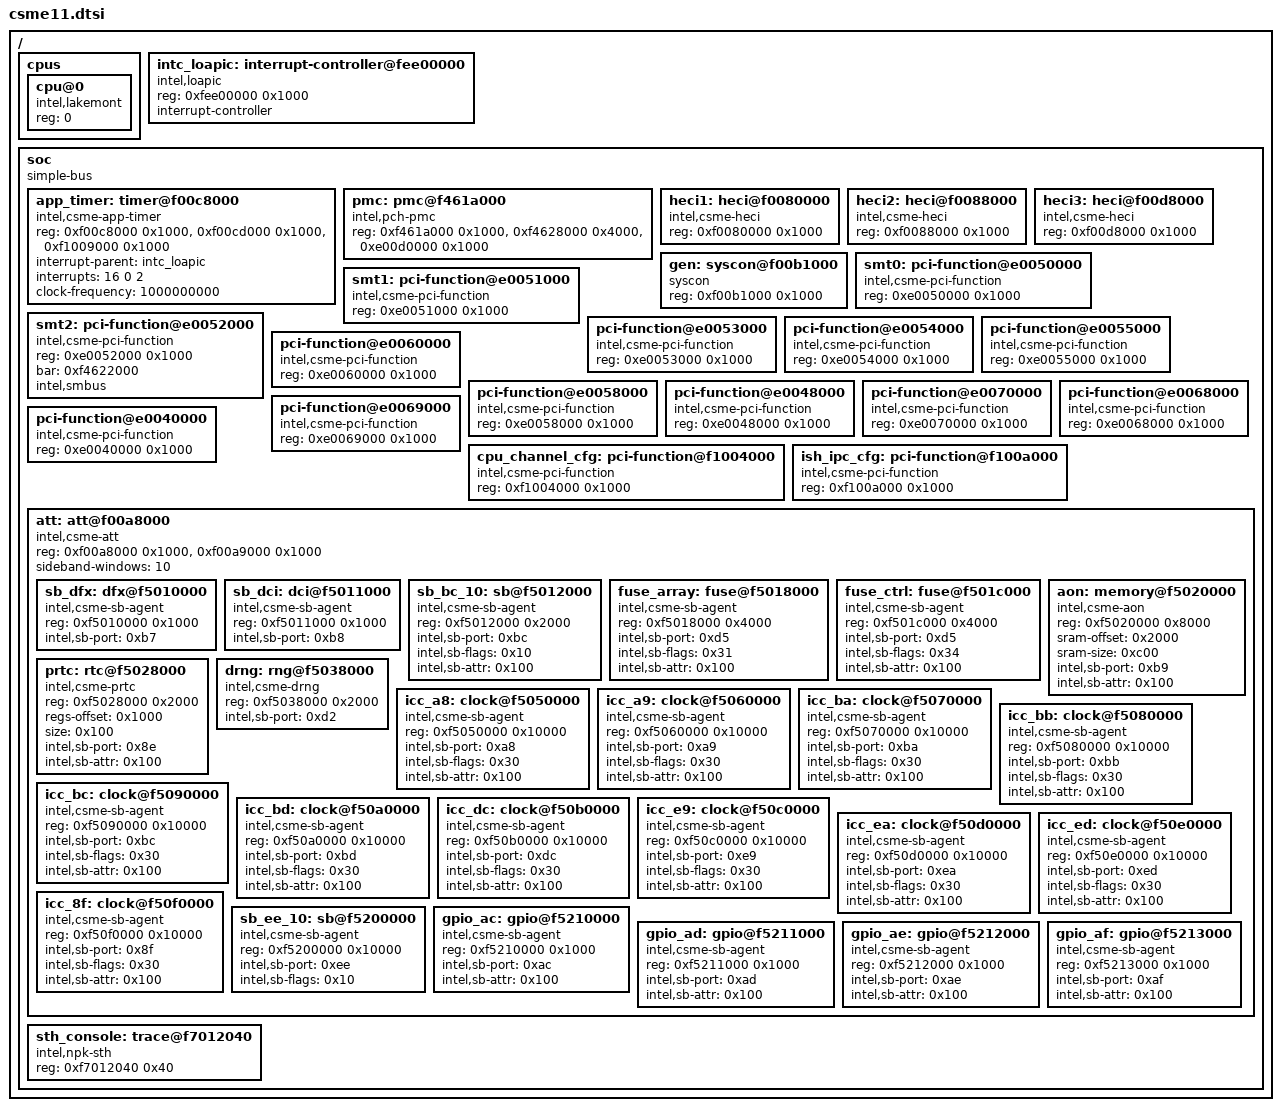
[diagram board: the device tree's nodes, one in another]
/*
 * Copyright The Zephyr Project Contributors
 *
 * SPDX-License-Identifier: Apache-2.0
 *
 * Intel CSME 11 (Sunrise Point PCH): the engine's view of its own address
 * space (csme-hardware-registers.md in the CSME reversing notes). Devices
 * behind ATT windows (the trace hub) are at the addresses the boot ROM maps
 * them to.
 */

#include <skeleton.dtsi>
#include <mem.h>

/ {
	cpus {
		#address-cells = <1>;
		#size-cells = <0>;

		cpu@0 {
			compatible = "intel,lakemont", "intel,x86";
			reg = <0>;
			device_type = "cpu";
		};
	};

	intc_loapic: interrupt-controller@fee00000 {
		compatible = "intel,loapic";
		reg = <0xfee00000 0x1000>;
		interrupt-controller;
		#interrupt-cells = <3>;
	};

	soc {
		compatible = "simple-bus";
		ranges;
		#address-cells = <1>;
		#size-cells = <1>;

		/* Private bus 0:01.1: BAR0, BAR5, configuration space. The
		 * interrupt is an MSI; IRQ numbers above the local APIC's LVT
		 * lines (0-5) are message-signalled only.
		 */
		app_timer: timer@f00c8000 {
			compatible = "intel,csme-app-timer";
			reg = <0xf00c8000 0x1000>, <0xf00cd000 0x1000>, <0xf1009000 0x1000>;
			reg-names = "regs", "ctl", "cfg";
			interrupt-parent = <&intc_loapic>;
			interrupts = <16 0 2>;
			/* the counter rate is inferred, not confirmed */
			clock-frequency = <1000000000>;
		};

		/* PCH PMC: root space 0:1a.0 (BAR0 registers, BAR1 SRAM) */
		pmc: pmc@f461a000 {
			compatible = "intel,pch-pmc";
			reg = <0xf461a000 0x1000>, <0xf4628000 0x4000>, <0xe00d0000 0x1000>;
			reg-names = "regs", "sram", "cfg";
		};

		/* HECI functions, engine side (fixed BARs on the private bus) */
		heci1: heci@f0080000 {
			compatible = "intel,csme-heci";
			reg = <0xf0080000 0x1000>;
		};

		heci2: heci@f0088000 {
			compatible = "intel,csme-heci";
			reg = <0xf0088000 0x1000>;
		};

		heci3: heci@f00d8000 {
			compatible = "intel,csme-heci";
			reg = <0xf00d8000 0x1000>;
		};

		/* CSME control (GEN): power-gate control, fabric drain */
		gen: syscon@f00b1000 {
			compatible = "syscon";
			reg = <0xf00b1000 0x1000>;
		};

		/* PCI functions the CSME kernel quiesces before a power transition
		 * (its device order), configuration space in the root ECAM or,
		 * for the last two, on the private bus
		 */
		smt0: pci-function@e0050000 {
			compatible = "intel,csme-pci-function";
			reg = <0xe0050000 0x1000>;
		};

		smt1: pci-function@e0051000 {
			compatible = "intel,csme-pci-function";
			reg = <0xe0051000 0x1000>;
		};

		smt2: pci-function@e0052000 {
			compatible = "intel,csme-pci-function";
			reg = <0xe0052000 0x1000>;
			bar = <0xf4622000>;
			intel,smbus;
		};

		pci-function@e0053000 {
			compatible = "intel,csme-pci-function";
			reg = <0xe0053000 0x1000>;
		};

		pci-function@e0054000 {
			compatible = "intel,csme-pci-function";
			reg = <0xe0054000 0x1000>;
		};

		pci-function@e0055000 {
			compatible = "intel,csme-pci-function";
			reg = <0xe0055000 0x1000>;
		};

		pci-function@e0060000 {
			compatible = "intel,csme-pci-function";
			reg = <0xe0060000 0x1000>;
		};

		pci-function@e0058000 {
			compatible = "intel,csme-pci-function";
			reg = <0xe0058000 0x1000>;
		};

		pci-function@e0048000 {
			compatible = "intel,csme-pci-function";
			reg = <0xe0048000 0x1000>;
		};

		pci-function@e0070000 {
			compatible = "intel,csme-pci-function";
			reg = <0xe0070000 0x1000>;
		};

		pci-function@e0068000 {
			compatible = "intel,csme-pci-function";
			reg = <0xe0068000 0x1000>;
		};

		pci-function@e0069000 {
			compatible = "intel,csme-pci-function";
			reg = <0xe0069000 0x1000>;
		};

		pci-function@e0040000 {
			compatible = "intel,csme-pci-function";
			reg = <0xe0040000 0x1000>;
		};

		cpu_channel_cfg: pci-function@f1004000 {
			compatible = "intel,csme-pci-function";
			reg = <0xf1004000 0x1000>;
		};

		ish_ipc_cfg: pci-function@f100a000 {
			compatible = "intel,csme-pci-function";
			reg = <0xf100a000 0x1000>;
		};

		/* Address translation table: primary and sideband windows. The
		 * sideband agents below are mapped on demand at these addresses
		 * (the ones the CSME kernel uses).
		 */
		att: att@f00a8000 {
			compatible = "intel,csme-att";
			reg = <0xf00a8000 0x1000>, <0xf00a9000 0x1000>;
			reg-names = "primary", "sideband";
			sideband-windows = <10>;
			#address-cells = <1>;
			#size-cells = <1>;
			ranges;

			/* DFX aggregator */
			sb_dfx: dfx@f5010000 {
				compatible = "intel,csme-sb-agent";
				reg = <0xf5010000 0x1000>;
				intel,sb-port = <0xb7>;
			};

			/* DCI */
			sb_dci: dci@f5011000 {
				compatible = "intel,csme-sb-agent";
				reg = <0xf5011000 0x1000>;
				intel,sb-port = <0xb8>;
			};

			/* Port 0xbc, flags 0x10 */
			sb_bc_10: sb@f5012000 {
				compatible = "intel,csme-sb-agent";
				reg = <0xf5012000 0x2000>;
				intel,sb-port = <0xbc>;
				intel,sb-flags = <0x10>;
				intel,sb-attr = <0x100>;
			};

			/* Fuse controller: shadow and sensed fuse data */
			fuse_array: fuse@f5018000 {
				compatible = "intel,csme-sb-agent";
				reg = <0xf5018000 0x4000>;
				intel,sb-port = <0xd5>;
				intel,sb-flags = <0x31>;
				intel,sb-attr = <0x100>;
			};

			/* Fuse controller: control (access grant, margin reads) */
			fuse_ctrl: fuse@f501c000 {
				compatible = "intel,csme-sb-agent";
				reg = <0xf501c000 0x4000>;
				intel,sb-port = <0xd5>;
				intel,sb-flags = <0x34>;
				intel,sb-attr = <0x100>;
			};

			/* AON agent: registers and always-on SRAM (+0x2000) */
			aon: memory@f5020000 {
				compatible = "intel,csme-aon";
				reg = <0xf5020000 0x8000>;
				sram-offset = <0x2000>;
				sram-size = <0xc00>;
				intel,sb-port = <0xb9>;
				intel,sb-attr = <0x100>;
			};

			/* PRTC: always-on registers (+0x1000) */
			prtc: rtc@f5028000 {
				compatible = "intel,csme-prtc";
				reg = <0xf5028000 0x2000>;
				regs-offset = <0x1000>;
				size = <0x100>;
				intel,sb-port = <0x8e>;
				intel,sb-attr = <0x100>;
			};

			/* DRNG */
			drng: rng@f5038000 {
				compatible = "intel,csme-drng";
				reg = <0xf5038000 0x2000>;
				intel,sb-port = <0xd2>;
			};

			/* ICC port 0xa8 */
			icc_a8: clock@f5050000 {
				compatible = "intel,csme-sb-agent";
				reg = <0xf5050000 0x10000>;
				intel,sb-port = <0xa8>;
				intel,sb-flags = <0x30>;
				intel,sb-attr = <0x100>;
			};

			/* ICC port 0xa9 */
			icc_a9: clock@f5060000 {
				compatible = "intel,csme-sb-agent";
				reg = <0xf5060000 0x10000>;
				intel,sb-port = <0xa9>;
				intel,sb-flags = <0x30>;
				intel,sb-attr = <0x100>;
			};

			/* ICC port 0xba */
			icc_ba: clock@f5070000 {
				compatible = "intel,csme-sb-agent";
				reg = <0xf5070000 0x10000>;
				intel,sb-port = <0xba>;
				intel,sb-flags = <0x30>;
				intel,sb-attr = <0x100>;
			};

			/* ICC port 0xbb */
			icc_bb: clock@f5080000 {
				compatible = "intel,csme-sb-agent";
				reg = <0xf5080000 0x10000>;
				intel,sb-port = <0xbb>;
				intel,sb-flags = <0x30>;
				intel,sb-attr = <0x100>;
			};

			/* ICC port 0xbc */
			icc_bc: clock@f5090000 {
				compatible = "intel,csme-sb-agent";
				reg = <0xf5090000 0x10000>;
				intel,sb-port = <0xbc>;
				intel,sb-flags = <0x30>;
				intel,sb-attr = <0x100>;
			};

			/* ICC port 0xbd */
			icc_bd: clock@f50a0000 {
				compatible = "intel,csme-sb-agent";
				reg = <0xf50a0000 0x10000>;
				intel,sb-port = <0xbd>;
				intel,sb-flags = <0x30>;
				intel,sb-attr = <0x100>;
			};

			/* ICC port 0xdc */
			icc_dc: clock@f50b0000 {
				compatible = "intel,csme-sb-agent";
				reg = <0xf50b0000 0x10000>;
				intel,sb-port = <0xdc>;
				intel,sb-flags = <0x30>;
				intel,sb-attr = <0x100>;
			};

			/* ICC port 0xe9 */
			icc_e9: clock@f50c0000 {
				compatible = "intel,csme-sb-agent";
				reg = <0xf50c0000 0x10000>;
				intel,sb-port = <0xe9>;
				intel,sb-flags = <0x30>;
				intel,sb-attr = <0x100>;
			};

			/* ICC port 0xea */
			icc_ea: clock@f50d0000 {
				compatible = "intel,csme-sb-agent";
				reg = <0xf50d0000 0x10000>;
				intel,sb-port = <0xea>;
				intel,sb-flags = <0x30>;
				intel,sb-attr = <0x100>;
			};

			/* ICC port 0xed */
			icc_ed: clock@f50e0000 {
				compatible = "intel,csme-sb-agent";
				reg = <0xf50e0000 0x10000>;
				intel,sb-port = <0xed>;
				intel,sb-flags = <0x30>;
				intel,sb-attr = <0x100>;
			};

			/* ICC port 0x8f */
			icc_8f: clock@f50f0000 {
				compatible = "intel,csme-sb-agent";
				reg = <0xf50f0000 0x10000>;
				intel,sb-port = <0x8f>;
				intel,sb-flags = <0x30>;
				intel,sb-attr = <0x100>;
			};

			/* Port 0xee, flags 0x10 */
			sb_ee_10: sb@f5200000 {
				compatible = "intel,csme-sb-agent";
				reg = <0xf5200000 0x10000>;
				intel,sb-port = <0xee>;
				intel,sb-flags = <0x10>;
			};

			/* GPIO communities (the CSME kernel maps them all at
			 * 0xf00b9000, one at a time)
			 */
			gpio_ac: gpio@f5210000 {
				compatible = "intel,csme-sb-agent";
				reg = <0xf5210000 0x1000>;
				intel,sb-port = <0xac>;
				intel,sb-attr = <0x100>;
			};

			gpio_ad: gpio@f5211000 {
				compatible = "intel,csme-sb-agent";
				reg = <0xf5211000 0x1000>;
				intel,sb-port = <0xad>;
				intel,sb-attr = <0x100>;
			};

			gpio_ae: gpio@f5212000 {
				compatible = "intel,csme-sb-agent";
				reg = <0xf5212000 0x1000>;
				intel,sb-port = <0xae>;
				intel,sb-attr = <0x100>;
			};

			gpio_af: gpio@f5213000 {
				compatible = "intel,csme-sb-agent";
				reg = <0xf5213000 0x1000>;
				intel,sb-port = <0xaf>;
				intel,sb-attr = <0x100>;
			};
		};

		/* An STH software channel of the trace hub (ATT window 3) */
		sth_console: trace@f7012040 {
			compatible = "intel,npk-sth";
			reg = <0xf7012040 0x40>;
		};
	};
};
